# S32K148_M4 register map
Vendor: NXP Semiconductors; File version: 1.1a
CPU: CM4 r0p1, little endian, MPU, FPU, VTOR, 4 interrupt priority bits
Registers are 32-bit, read-write, reset 0x0 unless marked. A register's access mark holds for its fields unless they carry their own. Offsets are from the block's base; [hi:lo] are bit positions; {n}, {i} and the like mark numbered series; 'fields as' and 'values as' point back to an identical list.

## EWM
Base 0x40061000
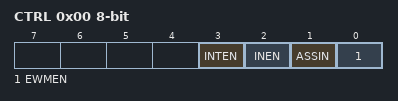
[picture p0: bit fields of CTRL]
0x00 CTRL 8-bit — Control Register
  [3] INTEN — Interrupt Enable.
  [2] INEN rw-once — Input Enable.
  [1] ASSIN rw-once — EWM_in's Assertion State Select.
  [0] EWMEN rw-once — EWM enable.
0x01 SERV 8-bit — Service Register
  [7:0] SERVICE
0x02 CMPL 8-bit rw-once — Compare Low Register
  [7:0] COMPAREL
0x03 CMPH 8-bit rw-once reset 0xFF — Compare High Register
  [7:0] COMPAREH
0x05 CLKPRESCALER 8-bit rw-once — Clock Prescaler Register
  [7:0] CLK_DIV

## TRGMUX
Base 0x40063000
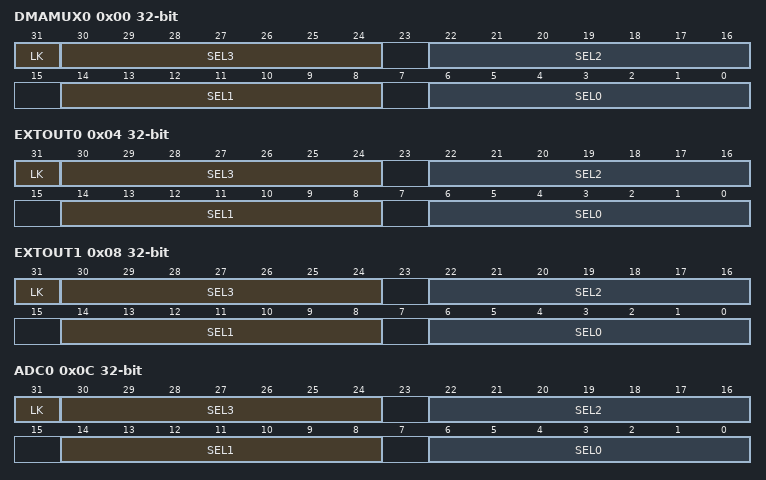
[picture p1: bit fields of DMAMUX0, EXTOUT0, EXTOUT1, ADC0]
0x00 DMAMUX0 — TRGMUX DMAMUX0 Register
  [31] LK — TRGMUX register lock.
    0=UNLOCKED (Register can be written.); 1=LOCKED (Register cannot be written until the next system Reset.)
  [8n+6:8n] SEL{n} (n=0..3) — Trigger MUX Input {n} Source Select
0x04 EXTOUT0 — TRGMUX EXTOUT0 Register
  fields as DMAMUX0
0x08 EXTOUT1 — TRGMUX EXTOUT1 Register
  fields as DMAMUX0
0x0C ADC0 — TRGMUX ADC0 Register
  fields as DMAMUX0
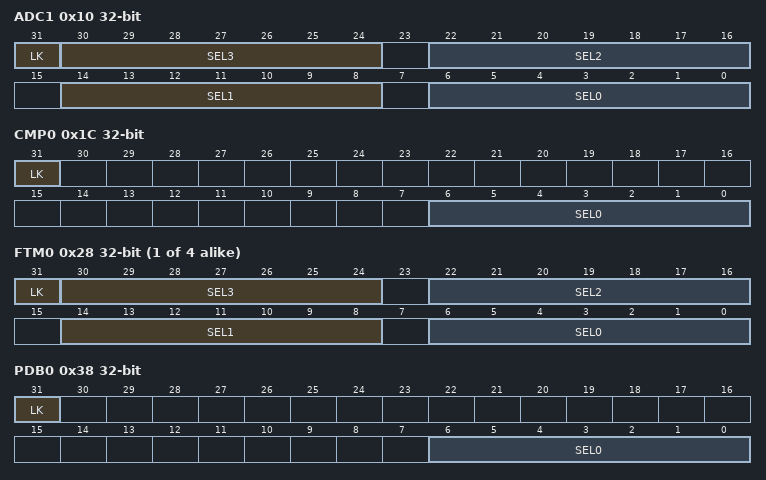
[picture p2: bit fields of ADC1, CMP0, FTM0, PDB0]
0x10 ADC1 — TRGMUX ADC1 Register
  fields as DMAMUX0
0x1C CMP0 — TRGMUX CMP0 Register
  [31] LK — TRGMUX register lock.
    values as DMAMUX0.LK
  [6:0] SEL0 — Trigger MUX Input 0 Source Select
{0x28+4i} FTM{i} (i=0..3) — TRGMUX FTM{i} Register
  fields as DMAMUX0
0x38 PDB0 — TRGMUX PDB0 Register
  fields as CMP0
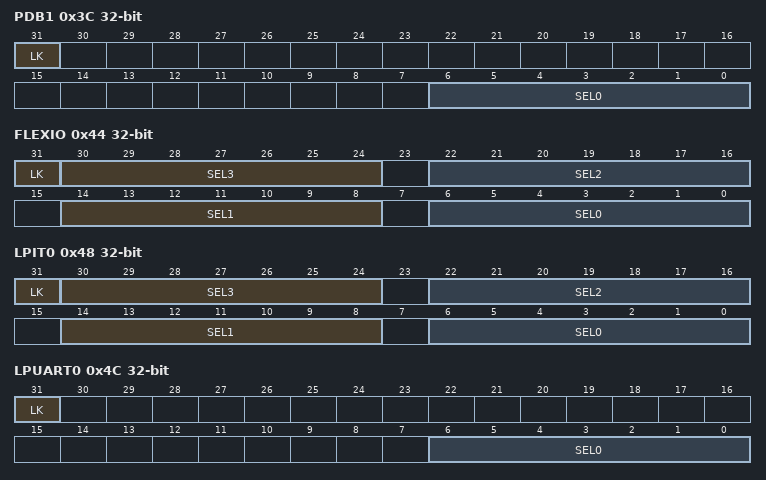
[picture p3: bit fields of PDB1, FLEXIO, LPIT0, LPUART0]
0x3C PDB1 — TRGMUX PDB1 Register
  fields as CMP0
0x44 FLEXIO — TRGMUX FLEXIO Register
  fields as DMAMUX0
0x48 LPIT0 — TRGMUX LPIT0 Register
  fields as DMAMUX0
0x4C LPUART0 — TRGMUX LPUART0 Register
  fields as CMP0
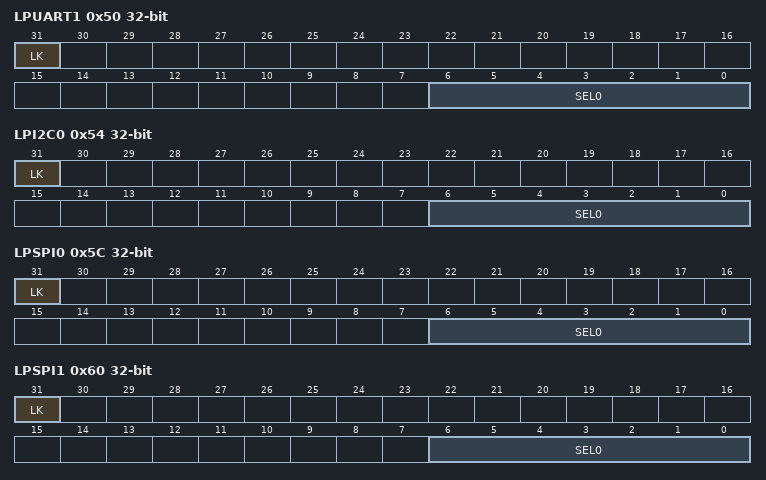
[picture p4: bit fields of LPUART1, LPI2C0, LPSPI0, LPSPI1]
0x50 LPUART1 — TRGMUX LPUART1 Register
  fields as CMP0
0x54 LPI2C0 — TRGMUX LPI2C0 Register
  fields as CMP0
0x5C LPSPI0 — TRGMUX LPSPI0 Register
  fields as CMP0
0x60 LPSPI1 — TRGMUX LPSPI1 Register
  fields as CMP0
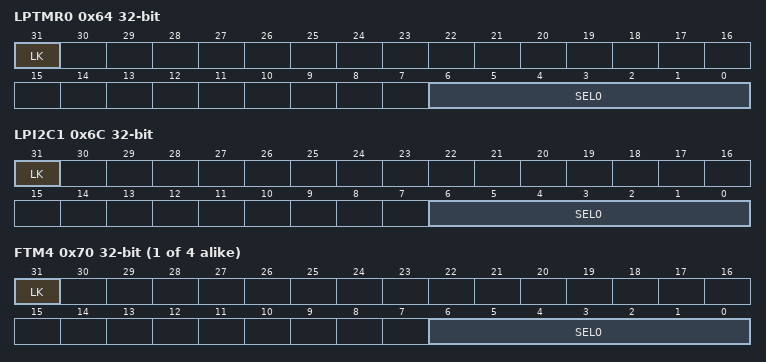
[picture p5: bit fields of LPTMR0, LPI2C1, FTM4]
0x64 LPTMR0 — TRGMUX LPTMR0 Register
  fields as CMP0
0x6C LPI2C1 — TRGMUX LPI2C1 Register
  fields as CMP0
{0x60+4i} FTM{i} (i=4..7) — TRGMUX FTM{i} Register
  fields as CMP0

## PCC
Base 0x40065000
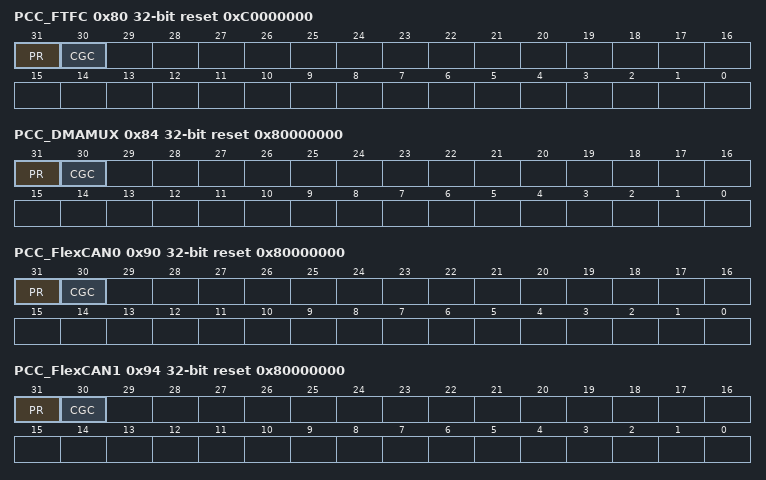
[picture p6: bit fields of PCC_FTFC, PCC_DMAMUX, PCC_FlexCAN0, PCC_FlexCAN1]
0x80 PCC_FTFC reset 0xC0000000
  [31] PR ro — Present
    0=NOT_PRESENT (Peripheral is not present.); 1=PRESENT (Peripheral is present.)
  [30] CGC — Clock Gate Control
    0=DISABLED (Clock disabled. The current clock selection and divider options are not locked and can be modified.); 1=ENABLED (Clock enabled. The current clock selection and divider options are locked and cannot be modified.)
0x84 PCC_DMAMUX reset 0x80000000
  fields as PCC_FTFC
0x90 PCC_FlexCAN0 reset 0x80000000
  fields as PCC_FTFC
0x94 PCC_FlexCAN1 reset 0x80000000
  fields as PCC_FTFC
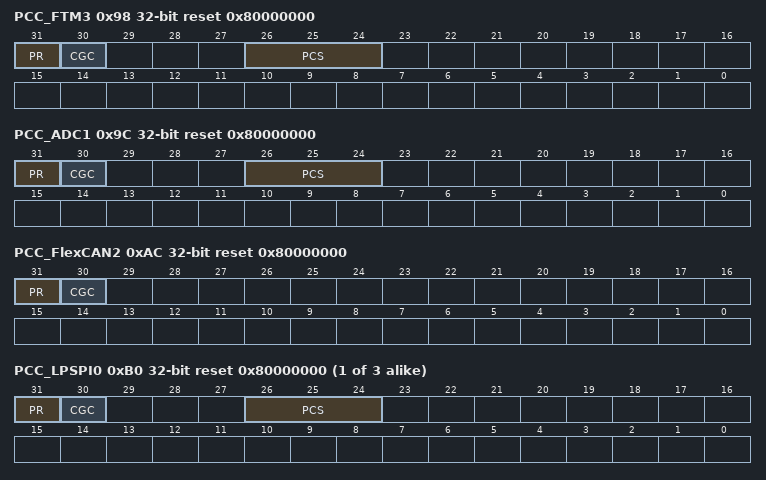
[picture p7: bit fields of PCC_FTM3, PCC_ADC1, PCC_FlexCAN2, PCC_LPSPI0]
0x98 PCC_FTM3 reset 0x80000000
  [31] PR ro — Present
    values as PCC_FTFC.PR
  [30] CGC — Clock Gate Control
    values as PCC_FTFC.CGC
  [26:24] PCS — Peripheral Clock Source Select
    0=CLOCK_EXT (Clock is off. An external clock can be enabled for this peripheral.); {v}=CLOCK_OPT{v} (Clock option {v}) (v=1..7)
0x9C PCC_ADC1 reset 0x80000000
  [31] PR ro — Present
    values as PCC_FTFC.PR
  [30] CGC — Clock Gate Control
    values as PCC_FTFC.CGC
  [26:24] PCS — Peripheral Clock Source Select
    0=CLOCK_OFF (Clock is off.); {v}=CLOCK_OPT{v} (Clock option {v}) (v=1..7)
0xAC PCC_FlexCAN2 reset 0x80000000
  fields as PCC_FTFC
{0xB0+4i} PCC_LPSPI{i} reset 0x80000000 (i=0..2)
  fields as PCC_ADC1
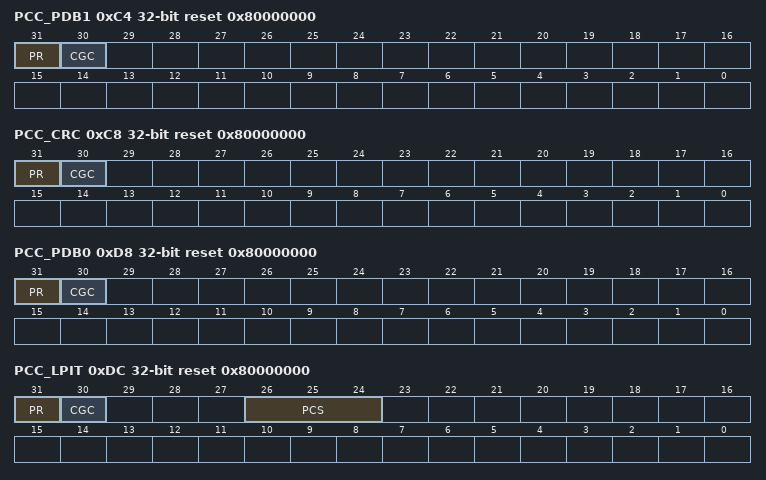
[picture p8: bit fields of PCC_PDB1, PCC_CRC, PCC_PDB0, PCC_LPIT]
0xC4 PCC_PDB1 reset 0x80000000
  fields as PCC_FTFC
0xC8 PCC_CRC reset 0x80000000
  fields as PCC_FTFC
0xD8 PCC_PDB0 reset 0x80000000
  fields as PCC_FTFC
0xDC PCC_LPIT reset 0x80000000
  fields as PCC_ADC1
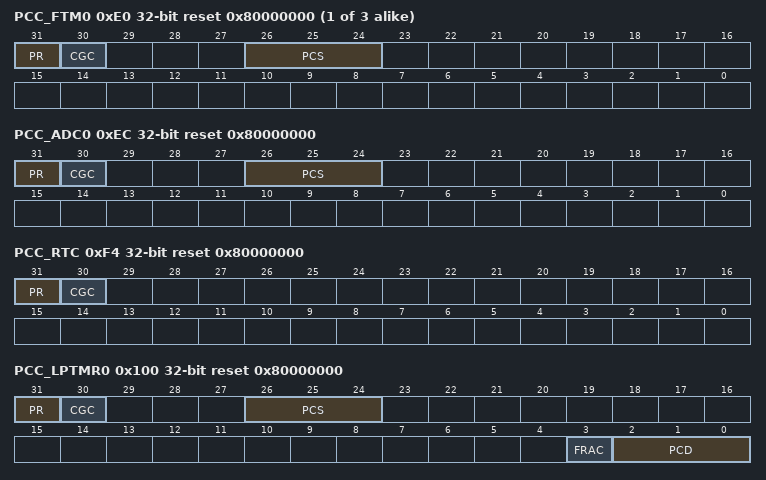
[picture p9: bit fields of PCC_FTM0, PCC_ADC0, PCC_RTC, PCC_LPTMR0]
{0xE0+4i} PCC_FTM{i} reset 0x80000000 (i=0..2)
  fields as PCC_FTM3
0xEC PCC_ADC0 reset 0x80000000
  fields as PCC_ADC1
0xF4 PCC_RTC reset 0x80000000
  fields as PCC_FTFC
0x100 PCC_LPTMR0 reset 0x80000000
  [31] PR ro — Present
    values as PCC_FTFC.PR
  [30] CGC — Clock Gate Control
    values as PCC_FTFC.CGC
  [26:24] PCS — Peripheral Clock Source Select
    values as PCC_ADC1.PCS
  [3] FRAC — Peripheral Clock Divider Fraction
    0=Fractional value is 0; 1=Fractional value is 1
  [2:0] PCD — Peripheral Clock Divider Select
    {v}=DIV_{v+1} (Divide by {v+1}.) (v=0..7)
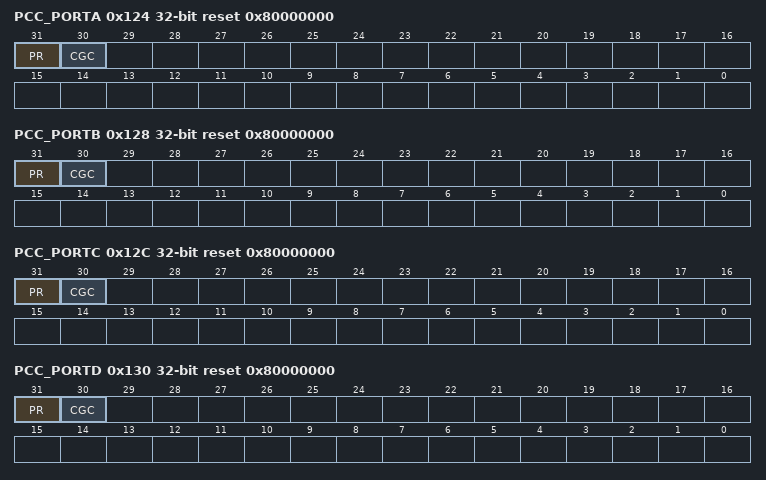
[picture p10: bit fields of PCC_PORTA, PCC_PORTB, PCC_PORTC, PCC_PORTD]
0x124 PCC_PORTA reset 0x80000000
  fields as PCC_FTFC
0x128 PCC_PORTB reset 0x80000000
  fields as PCC_FTFC
0x12C PCC_PORTC reset 0x80000000
  fields as PCC_FTFC
0x130 PCC_PORTD reset 0x80000000
  fields as PCC_FTFC
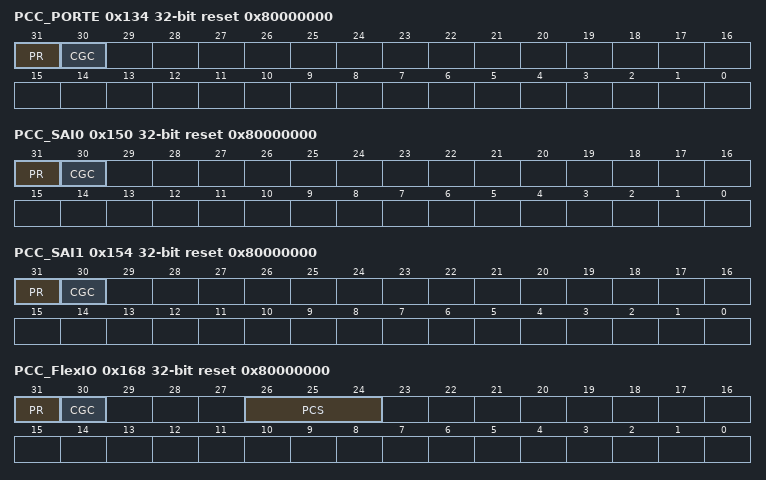
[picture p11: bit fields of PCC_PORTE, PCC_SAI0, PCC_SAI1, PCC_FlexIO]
0x134 PCC_PORTE reset 0x80000000
  fields as PCC_FTFC
0x150 PCC_SAI0 reset 0x80000000
  fields as PCC_FTFC
0x154 PCC_SAI1 reset 0x80000000
  fields as PCC_FTFC
0x168 PCC_FlexIO reset 0x80000000
  fields as PCC_ADC1
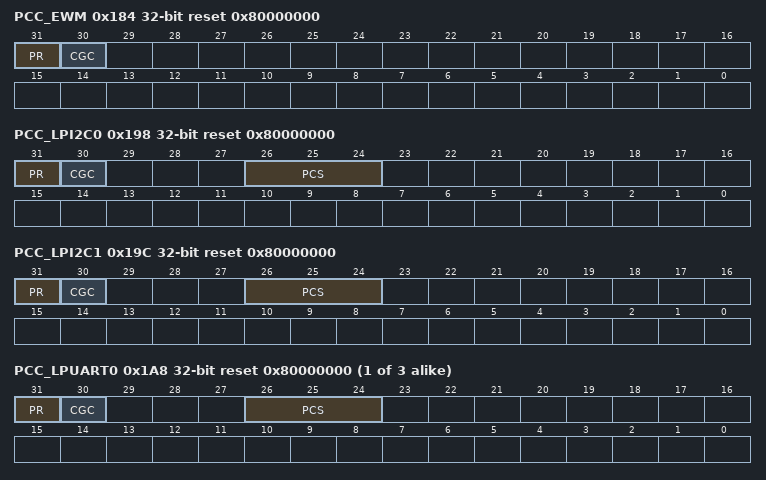
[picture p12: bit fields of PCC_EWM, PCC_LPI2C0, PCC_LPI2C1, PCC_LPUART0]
0x184 PCC_EWM reset 0x80000000
  fields as PCC_FTFC
0x198 PCC_LPI2C0 reset 0x80000000
  fields as PCC_ADC1
0x19C PCC_LPI2C1 reset 0x80000000
  fields as PCC_ADC1
{0x1A8+4i} PCC_LPUART{i} reset 0x80000000 (i=0..2)
  fields as PCC_ADC1
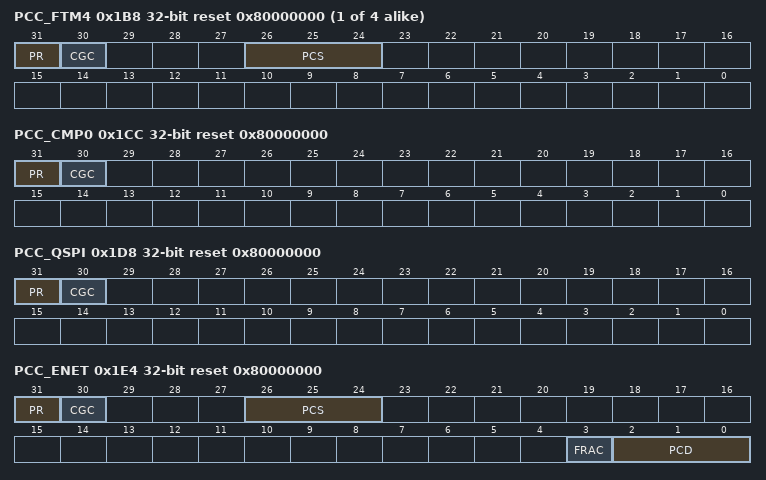
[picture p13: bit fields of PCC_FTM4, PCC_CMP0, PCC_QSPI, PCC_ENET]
{0x1A8+4i} PCC_FTM{i} reset 0x80000000 (i=4..7)
  fields as PCC_FTM3
0x1CC PCC_CMP0 reset 0x80000000
  fields as PCC_FTFC
0x1D8 PCC_QSPI reset 0x80000000
  fields as PCC_FTFC
0x1E4 PCC_ENET reset 0x80000000
  fields as PCC_LPTMR0
